# AT32UC3C0512C device description
Architecture: AVR32_UC3; Family: AVR UC3
Registers are 32-bit, read-write, reset 0x0 unless marked. A register's access mark holds for its fields unless they carry their own. Offsets are from the block's base; [hi:lo] are bit positions; {n}, {i} and the like mark numbered series.

## SAU — Secure Access Unit
Instances: SAU 0xfffe2400, SAU_HSB 0x90000000 in hsb
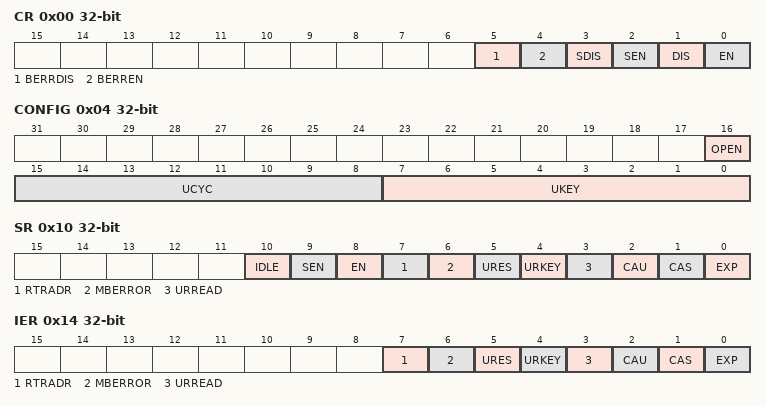
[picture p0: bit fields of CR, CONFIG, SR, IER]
0x00 CR wo reset not defined — Control Register
  [5] BERRDIS — Bus Error Response Disable
  [4] BERREN — Bus Error Response Enable
  [3] SDIS — Setup Mode Disable
  [2] SEN — Setup Mode Enable
  [1] DIS — SAU Disable
  [0] EN — SAU Enable
0x04 CONFIG wo — Configuration Register
  [16] OPEN — Open Mode Enable
  [15:8] UCYC — Unlock number of clock cycles
  [7:0] UKEY — Unlock Key
0x08 CERH — Channel Enable Register High
  [30:0] CERH
0x0C CERL — Channel Enable Register Low
0x10 SR ro — Status Register
  [10] IDLE — SAU Master Interface Idle
  [9] SEN — SAU Setup Mode Enabled
  [8] EN — SAU Enabled
  [7] RTRADR — RTR Address Error
  [6] MBERROR — Master Interface Bus Error
  [5] URES — Unlock Register Error
  [4] URKEY — Unlock Register Key Error
  [3] URREAD — Unlock Register Read
  [2] CAU — Channel Access Unsuccessful
  [1] CAS — Channel Access Successful
  [0] EXP — Channel Unlock Expired
0x14 IER wo reset not defined — Interrupt Enable Register
  [7] RTRADR — Enable Illegal RTR Address Setup Interrupt
  [6] MBERROR — Enable Master Interface Bus Error Interrupt
  [5] URES — Enable Unlock Register Error Interrupt
  [4] URKEY — Enable Unlock Register Key Error Interrupt
  [3] URREAD — Enable Unlock Register Read Interrupt
  [2] CAU — Enable Channel Access Unsuccessful Interrupt
  [1] CAS — Enable Channel Access Successful Interrupt
  [0] EXP — Enable Channel Unlock Expired Interrupt
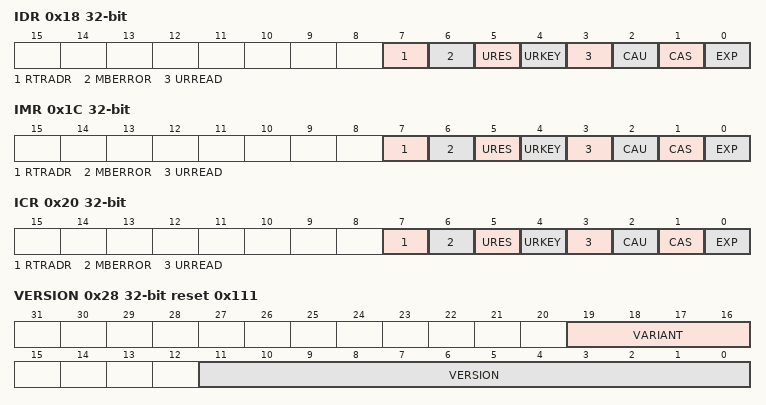
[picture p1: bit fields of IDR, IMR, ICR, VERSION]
0x18 IDR wo reset not defined — Interrupt Disable Register
  [7] RTRADR — Disable Illegal RTR Address Setup Interrupt
  [6] MBERROR — Disable Master Interface Bus Error Interrupt
  [5] URES — Disable Inlock Register Error Interrupt
  [4] URKEY — Disable Unlock Register Key Error Interrupt
  [3] URREAD — Disable Unlock Register Read Interrupt
  [2] CAU — Disable Channel Access Unsuccessful Interrupt
  [1] CAS — Disable Channel Access Successful Interrupt
  [0] EXP — Disable Channel Unlock Expired Interrupt
0x1C IMR ro — Interrupt Mask Register
  [7] RTRADR — Illegal RTR Address Setup Interrupt Mask Bit
  [6] MBERROR — Master Interface Bus Error Interrupt Mask Bit
  [5] URES — Unlock Register Error Interrupt Mask Bit
  [4] URKEY — Unlock Register Key Error Interrupt Mask Bit
  [3] URREAD — Unlock Register Read Interrupt Mask Bit
  [2] CAU — Channel Access Unsuccessful Interrupt Mask Bit
  [1] CAS — Channel Access Successful Interrupt Mask Bit
  [0] EXP — Channel Unlock Expired Interrupt Mask Bit
0x20 ICR wo reset not defined — Interrupt Clear Register
  [7] RTRADR — Clear Illegal RTR Address Setup bit
  [6] MBERROR — Clear Master Interface Bus Error bit
  [5] URES — Clear Unlock Register Error bit
  [4] URKEY — Clear Unlock Register Key Error bit
  [3] URREAD — Clear Unlock Register Read bit
  [2] CAU — Clear Channel Access Unsuccessful bit
  [1] CAS — Clear Channel Access Successful bit
  [0] EXP — Clear Channel Unlock Expired bit
0x24 PARAMETER ro reset 0x10
  [5:0] CHANNELS — SAU Parameters
0x28 VERSION ro reset 0x111
  [19:16] VARIANT — Variant number
  [11:0] VERSION — Version number

## SAU_HSB — Secure Access Unit
{0x0+4i} RTR[{i}] (i=0..62) access not given reset not defined
  [31:0] RTR — Remap Target Address for channel n
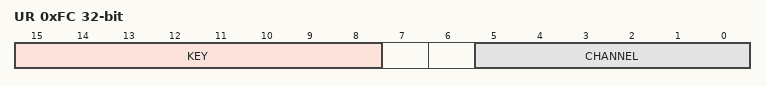
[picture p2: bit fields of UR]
0xFC UR wo reset not defined — Unlock Register
  [15:8] KEY — Unlock Key
  [5:0] CHANNEL — Channel number

## SDRAMC — SDRAM Controller
Instances: SDRAMC 0xfffe2c00
0x00 MR — SDRAMC Mode Register
  [2:0] MODE — SDRAMC Command Mode
    0=NORMAL; 1=NOP; 2=BANKS_PRECHARGE; 3=LOAD_MODE; 4=AUTO_REFRESH; 5=EXT_LOAD_MODE; 6=POWER_DOWN
0x04 TR — SDRAMC Refresh Timer Register
  [11:0] COUNT — SDRAMC Refresh Timer Count
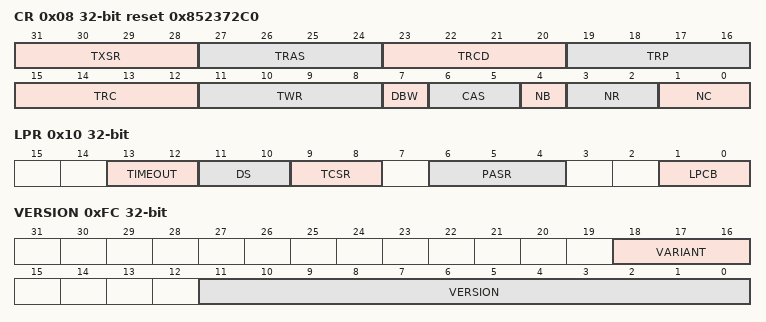
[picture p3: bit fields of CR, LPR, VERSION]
0x08 CR reset 0x852372C0 — SDRAMC Configuration Register
  [31:28] TXSR — Exit Self Refresh to Active Delay
  [27:24] TRAS — Active to Precharge Delay
  [23:20] TRCD — Row to Column Delay
  [19:16] TRP — Row Precharge Delay
  [15:12] TRC — Row Cycle Delay
  [11:8] TWR — Write Recovery Delay
  [7] DBW — Data Bus Width
    0=32_BITS; 1=16_BITS
  [6:5] CAS — CAS Latency
    1=ONE_CYCLE; 2=TWO_CYCLES; 3=THREE_CYCLES
  [4] NB — Number of Banks
    0=TWO_BANKS; 1=FOUR_BANKS
  [3:2] NR — Number of Row Bits
    0=11_ROW_BITS; 1=12_ROW_BITS; 2=13_ROW_BITS
  [1:0] NC — Number of Column Bits
    {v}={v+8}_COLUMN_BITS (v=0..3)
0x0C HSR — SDRAMC High Speed Register
  [0] DA — Decode Cycle Enable
0x10 LPR — SDRAMC Low Power Register
  [13:12] TIMEOUT — Time to define when low-power mode is enabled
    0=AFTER_END; 1=64_CYC_AFTER_END; 2=128_CYC_AFTER_END
  [11:10] DS — Drive Strength (only for low-power SDRAM)
  [9:8] TCSR — Temperature Compensated Self-Refresh (only for low-power SDRAM)
  [6:4] PASR — Partial Array Self-refresh (only for low-power SDRAM)
  [1:0] LPCB — Low-power Configuration Bits
    0=NO_LP; 1=SELF_REFRESH; 2=POWER_DOWN; 3=DEEP_POWER_DOWN
0x14 IER wo reset not defined — SDRAMC Interrupt Enable Register
  [0] RES — Refresh Error Status
0x18 IDR wo reset not defined — SDRAMC Interrupt Disable Register
  [0] RES — Refresh Error Status
0x1C IMR ro — SDRAMC Interrupt Mask Register
  [0] RES — Refresh Error Status
0x20 ISR ro — SDRAMC Interrupt Status Register
  [0] RES — Refresh Error Status
0x24 MDR — SDRAMC Memory Device Register
  [1:0] MD — Memory Device Type
    0=SDRAM; 1=LOW_POWER_SDRAM
0xEC ADDRSIZE ro — SDRAMC Addresse Size Register
0xF0 NAME1 ro — SDRAMC Name1 Register
0xF4 NAME2 ro — SDRAMC Name2 Register
0xFC VERSION ro — SDRAMC Version Register
  [18:16] VARIANT, [11:0] VERSION
